# MCU_I3C0_VBP2APB_WRAP_CORE_VBP_MIPI_I3C_MST register map
Vendor: Texas Instruments
Registers are 32-bit, read-write, reset 0x0 unless marked. A register's access mark holds for its fields unless they carry their own. Offsets are as the file gives them; [hi:lo] are bit positions; {n}, {i} and the like mark numbered series; 'fields as' and 'values as' point back to an identical list.

## MCU_I3C0_VBP2APB_WRAP_CORE_VBP_MIPI_I3C_MST (part 2 of 2)
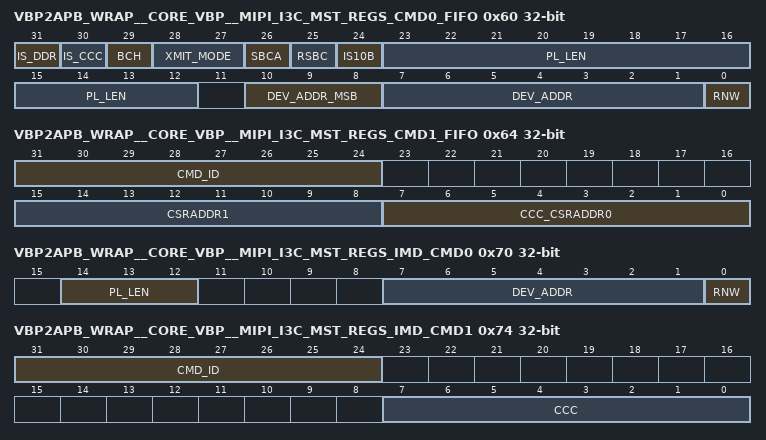
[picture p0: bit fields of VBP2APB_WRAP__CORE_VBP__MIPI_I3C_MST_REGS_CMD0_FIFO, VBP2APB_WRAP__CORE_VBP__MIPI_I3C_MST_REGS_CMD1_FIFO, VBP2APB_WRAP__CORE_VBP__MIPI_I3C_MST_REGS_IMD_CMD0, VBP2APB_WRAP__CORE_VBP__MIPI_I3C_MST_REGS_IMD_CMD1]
0x60 VBP2APB_WRAP__CORE_VBP__MIPI_I3C_MST_REGS_CMD0_FIFO wo — Command Word 0 - commands are executed sequentially in order of arrival from the host.
  [31] IS_DDR — IS_DDR - DDR command. Enables DDR mode of transfer. 0 - SDR mode 1 - DDR mode, note that ENTHDR-DDR CCC should precede any commands with DDR mode enabled.
  [30] IS_CCC — IsCCC. Denotes whether it is a CCC or generic command. 0 - generic command 1 - CCC command
  [29] BCH — BCH - Broadcast Header. Defines whether command will includes broadcast address header [0x7E] or not. Implicitly set for CCC commands. 0 - broadcast header disabled 1 - broadcast header enabled
  [28:27] XMIT_MODE — Defines transfer modes for I3C SDR private read/write commands [not CCC], the following options are available: 00 - burst [byte-by-byte] transfer with static register sub-address. Send static sub-address followed by data bytes only. 01 - single data byte transfers with auto incremented register sub-addressing. Each data byte is followed by repeated start condition and slave's sub-address is inremented explicitly. 10 - single data byte transfers without auto incremented register sub-addressing. Each data byte is followed by repeated start condition, register sub-address as in CMD descriptor for all transactions. 11 - burst [byte-by-byte] transfer without register sub-addressing, i.e. first data byte after the DA/SA is payload byte acquired from Tx DATA buffer.
  [26] SBCA — SBCA - Sixteen Bits CSR Addressing. Defines the CSR addressing mode for I3C private commands only. 0 - normal CSR addressing mode [8-bit] - ADDR0_7 - ADDR0_0 1 - extended CSR addressing mode [16-bit] - ADDR0_7 - ADDR0_0 and ADDR1_7 - ADDR1_0
  [25] RSBC — RSBC - Repeated Start Between Commands. When this bit is set then between commands he repeated start condition is issued instead stop condition. It is only applicable when there is more than one command is in the command queue and next command is for Slave device of same type. The stop condition will be generated regardless of RSCB bit value for the following scenarios: - current command is the last command in the command queue - next command has invalid DA/SA - immediate command comes through
  [24] IS10B — Is10B - Normal/Extended Address. Defines the addressing mode, applicable only for legacy I2C messaging. 0 - normal addressing mode [7-bit] - ID6-ID0 1 - extended addressing mode [10-bit] - ID10B2-ID10B0 and ID6-ID0
  [23:12] PL_LEN — PL_LEN - Payload Length, defines number of bytes to be sent for particular CCC or generic R/Q command. Supports up to 4095 bytes.
  [10:8] DEV_ADDR_MSB — DEV_ADDR_MSB - legacy I2C Extended Address. The 3 MSB bits of legacy I2C 10-bit address. Applicable only if Is_10B is set for I2C legacy transfers.
  [7:1] DEV_ADDR — DEV_ADDR - Static/Dynamic slave Address. Correspond to a given slave Dynamic Address and Static Address. For CCC is applicable only when it is direct CCC command. For broadcast CCC this field is ignored.
  [0] RNW — RnW - Read no Write. Defines the direction of transfer, for broadcast CCC this field is ignored. 0 - Write Transfer 1 - Read Transfer
0x64 VBP2APB_WRAP__CORE_VBP__MIPI_I3C_MST_REGS_CMD1_FIFO wo — Command Word 1 - commands are executed sequentially in order of arrival from host.
  [31:24] CMD_ID — CMD_ID - command identifier.
  [15:8] CSRADDR1 — CSR ADDR1 - second byte of the CSR address in 16-bit addressing mode. Applicable only when 16-bit addressing mode is used and for private commands [non CCC commands].
  [7:0] CCC_CSRADDR0 — CCC/CSR ADDR0 - CCC or CSR Address. Meaning of this field depends on bit 30 [IsCCC] of Command Word0. - When is_ccc is set to '0' then this field holds address of slave CSR. When 16-bit addressing is used, then it is the first byte of the CSR address. - When is ccc is set to '1' then this field holds code of CCC.
0x68 VBP2APB_WRAP__CORE_VBP__MIPI_I3C_MST_REGS_TX_FIFO wo — Tx DATA Buffer that stores payload to be send with associated Tx command descriptor (from regular Command Queue).
  [31:0] DATA — Tx DATA payload.
0x70 VBP2APB_WRAP__CORE_VBP__MIPI_I3C_MST_REGS_IMD_CMD0 wo — Immediate Command Word 0 - High priority command register. If host submits immediate command when controller is during execution of regular command, the core will run regular command to completion and then will execute the immediate command, disregarding state of Command Queue. Supposed to be used mainly for CCC commands with payload up to 4 bytes.
  [14:12] PL_LEN — PL_LEN - Payload Length, defines number of bytes to be send for particular CCC or generic R/W command. Supports up to 4 bytes.
  [7:1] DEV_ADDR — DEV_ADDR - Static/Dynamic slave Address. Correspond to a given slave Dynamic Address and Static Address. For CCC is applicable only when it is direct CCC command. For broadcast CCC this field is ignored.
  [0] RNW — RnW - Read not Write. Defines the direction of transfer, for broadcast CCC this field is ignored. 0 - Write Transfer 1 - Read Transfer
0x74 VBP2APB_WRAP__CORE_VBP__MIPI_I3C_MST_REGS_IMD_CMD1 wo — Immediate Command Word 1 - High priority command register. If host submits immediate command when controller is during execution of regular command, the core will run regular command to completion and then will execute the immediate command, disregarding state of Command Queue. Supposed to be used mainly for CCC commands with payload up to 4 bytes.
  [31:24] CMD_ID — CMD_ID - command identifier.
  [7:0] CCC — CCC Code - field holds code of CCC message.
0x78 VBP2APB_WRAP__CORE_VBP__MIPI_I3C_MST_REGS_IMD_DATA — Tx DATA Register that stores payload to be send with associated command descriptor (from Immediate Command Register).
  [31:0] DATA — Tx DATA payload [it's not a FIFO, supports up to 4 bytes only].
0x80 VBP2APB_WRAP__CORE_VBP__MIPI_I3C_MST_REGS_RX_FIFO ro — Rx DATA Buffer that stores payload received as a part of Rx command execution (from regular Command Queue).
  [31:0] DATA — Rx DATA payload.
0x84 VBP2APB_WRAP__CORE_VBP__MIPI_I3C_MST_REGS_IBI_DATA_FIFO ro — IBI Data Buffer that stores payload received as apart of IBI reuqest service.
  [31:0] DATA — IBI DATA payload.
0x88 VBP2APB_WRAP__CORE_VBP__MIPI_I3C_MST_REGS_SLV_DDR_TX_FIFO wo — Slave DDR Tx DATA Buffer that stores payload to be send upon reception of DDR read request from Current Master.
  [19:0] DDR_SLAVE_TX_DATA_FIFO — DDR Tx DATA payload [with meta-data, e.g. preamble/parity].
0x8C VBP2APB_WRAP__CORE_VBP__MIPI_I3C_MST_REGS_SLV_DDR_RX_FIFO ro — Slave DDR Rx DATA Buffer that stores payload received during reception of DDR write request from Current Master.
  [19:0] DDR_SLAVE_RX_DATA_FIFO — DDR Rx DATA payload [with meta-data, e.g. preamble/parity].
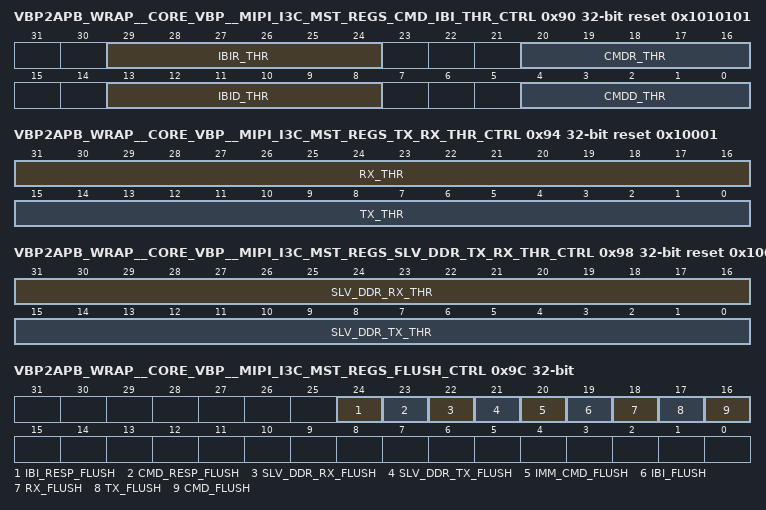
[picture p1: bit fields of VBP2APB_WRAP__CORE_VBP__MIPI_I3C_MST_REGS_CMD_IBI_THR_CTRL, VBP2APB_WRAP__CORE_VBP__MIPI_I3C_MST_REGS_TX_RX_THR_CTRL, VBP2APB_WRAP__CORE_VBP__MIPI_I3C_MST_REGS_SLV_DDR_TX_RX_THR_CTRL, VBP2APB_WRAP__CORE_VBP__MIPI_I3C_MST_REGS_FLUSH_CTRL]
0x90 VBP2APB_WRAP__CORE_VBP__MIPI_I3C_MST_REGS_CMD_IBI_THR_CTRL reset 0x1010101 — Control register for threshold generation - associated with Command and In-Band Interrupt memory blocks.
  [29:24] IBIR_THR — Threshold configuration value for IBI Response Queue.
  [20:16] CMDR_THR — Threshold configuration value for Command Response Queue.
  [13:8] IBID_THR — Threshold configuration value for IBI DATA Buffer.
  [4:0] CMDD_THR — Threshold configuration value for Command Queue.
0x94 VBP2APB_WRAP__CORE_VBP__MIPI_I3C_MST_REGS_TX_RX_THR_CTRL reset 0x10001 — Control register for threshold generation - associated with Tx and Rx DATA memory blocks.
  [31:16] RX_THR — Threshold configuration value for Rx Data memory block
  [15:0] TX_THR — Threshold configuration value for Tx Data memory block
0x98 VBP2APB_WRAP__CORE_VBP__MIPI_I3C_MST_REGS_SLV_DDR_TX_RX_THR_CTRL reset 0x10001 — Control register for threshold generation - associated with Slave Mode DDR Tx and Rx DATA memory blocks.
  [31:16] SLV_DDR_RX_THR — Threshold configuration value for Slave DDR Rx DATA buffer.
  [15:0] SLV_DDR_TX_THR — Threshold configuration value for Slave DDR Tx DATA buffer.
0x9C VBP2APB_WRAP__CORE_VBP__MIPI_I3C_MST_REGS_FLUSH_CTRL wo — Soft flush control for memory blocks.
  [24] IBI_RESP_FLUSH — When asserted while controller is disabled, the IBI Response Queue read/write pointers will be set to 0, effectively makes the buffer empty. Self-cleared control bit.
  [23] CMD_RESP_FLUSH — When asserted while controller is disabled, the Command Response Queue read/write pointers will be set to 0, effectively makes the buffer empty. Self-cleared control bit.
  [22] SLV_DDR_RX_FLUSH — When asserted while controller is disabled, the Slave DDR Rx DATA Buffer read/write pointers will be set to 0, effectively makes the buffer empty. Self-cleared control bit.
  [21] SLV_DDR_TX_FLUSH — When asserted while controller is disabled, the Slave DDR Tx DATA Buffer read/write pointers will be set to 0, effectively makes the buffer empty. Self-cleared control bit.
  [20] IMM_CMD_FLUSH — When asserted while controller is disabled, the Immediate Commadn/DATA registers will be cleared and their empty flag will be asserted. Self-cleared control bit.
  [19] IBI_FLUSH — When asserted while controller is disabled, the IBI DATA Buffer read/write pointers will be set to 0, effectively makes the buffer empty. Self-cleared control bit.
  [18] RX_FLUSH — When asserted while controller is disabled, the Rx DATA Buffer read/write pointers will be set to 0, effectively makes the buffer empty. Self-cleared control bit.. Self-cleared control bit.
  [17] TX_FLUSH — When asserted while controller is disabled, the Tx DATA Buffer read/write pointers will be set to 0, effectively makes the buffer empty. Self-cleared control bit.
  [16] CMD_FLUSH — When asserted while controller is disabled, the Command Buffer read/write pointers will be set to 0, effectively makes the buffer empty. Self-cleared control bit.
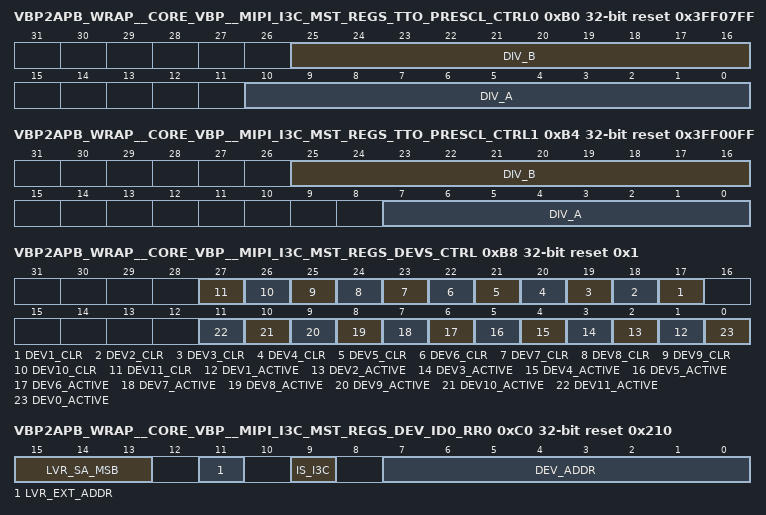
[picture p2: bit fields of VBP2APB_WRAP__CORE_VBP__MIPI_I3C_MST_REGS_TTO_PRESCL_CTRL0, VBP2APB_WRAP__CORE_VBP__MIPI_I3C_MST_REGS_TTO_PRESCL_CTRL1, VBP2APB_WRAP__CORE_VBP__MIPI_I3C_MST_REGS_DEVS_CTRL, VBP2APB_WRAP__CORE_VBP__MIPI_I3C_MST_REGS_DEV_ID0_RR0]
0xB0 VBP2APB_WRAP__CORE_VBP__MIPI_I3C_MST_REGS_TTO_PRESCL_CTRL0 reset 0x3FF07FF — Prescale settings for First SCL high timeout detection.
  [25:16] DIV_B — Divider B
  [10:0] DIV_A — Divider A
0xB4 VBP2APB_WRAP__CORE_VBP__MIPI_I3C_MST_REGS_TTO_PRESCL_CTRL1 reset 0x3FF00FF — Prescale settings for SCL high and low timeout detection.
  [25:16] DIV_B — Divider B
  [7:0] DIV_A — Divider A
0xB8 VBP2APB_WRAP__CORE_VBP__MIPI_I3C_MST_REGS_DEVS_CTRL access per field reset 0x1 — Device control register.
  [n+16] DEV{n}_CLR wo (n=1..11) — Clear contents of DevID{n} retaining registers. Self-cleared bit.
  [n] DEV{n}_ACTIVE rw (n=1..11) — DevID{n} is active - has either valid DA or SA.
  [0] DEV0_ACTIVE ro — DevID0 is active - has either valid DA or SA.
0xC0 VBP2APB_WRAP__CORE_VBP__MIPI_I3C_MST_REGS_DEV_ID0_RR0 access per field reset 0x210 — Device ID 0 Retaining Register 0 : Configuration Register
  [15:13] LVR_SA_MSB rw — MSB bits of Legacy I2C Device with 10-bit addressing.
  [11] LVR_EXT_ADDR rw — Device 0 Address mode used: 0 - 7-bit addressing - applicable for I3C and I2C devices. 1 - 10-bit addressing - applicable only for I2C devices with 10-bit extended address. NOTE: Invalid setting when Device0_RR0.is_i3c=1
  [9] IS_I3C ro — Device 0 I3C mode Operation 1 Yes 0 No
  [7:0] DEV_ADDR rw — Device 0 Slave Dynamic [Static/Legacy] Address bits 7:1 bit 0 - parity XOR check -> ~XOR[dev_addr[7:1]].
0xC4 VBP2APB_WRAP__CORE_VBP__MIPI_I3C_MST_REGS_DEV_ID0_RR1 reset 0x2040000 — Device ID 0 Retaining Register 1 : Provisional ID MSB 32-bits
  [31:0] PID_MSB — Device 0 48 to 16 Dev ID bits
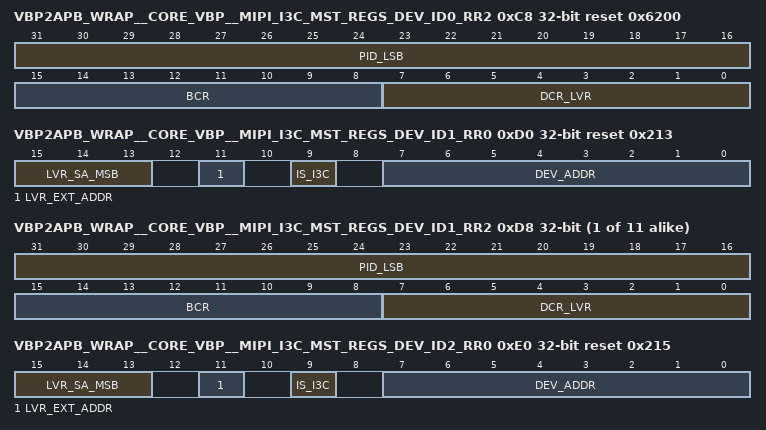
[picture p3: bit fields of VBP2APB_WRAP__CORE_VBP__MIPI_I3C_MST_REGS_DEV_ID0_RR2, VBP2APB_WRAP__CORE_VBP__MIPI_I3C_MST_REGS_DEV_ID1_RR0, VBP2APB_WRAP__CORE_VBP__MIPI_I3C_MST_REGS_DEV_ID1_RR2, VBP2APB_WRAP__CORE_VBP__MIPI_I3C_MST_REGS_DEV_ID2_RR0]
0xC8 VBP2APB_WRAP__CORE_VBP__MIPI_I3C_MST_REGS_DEV_ID0_RR2 reset 0x6200 — Device ID 0 Retaining Register 2 : Provisional ID LSB 16-bits, BCR, DCR or LVR (for legacy Mode)
  [31:16] PID_LSB — Device 0 15 to 0 Dev ID bits
  [15:8] BCR — Device 0 BCR register
  [7:0] DCR_LVR — Device 0 DCR [if I3C device] or LVR [if I2C device] register Decoding if used as DCR: Bits[7:0]: 255 available codes for describing the type of sensor, or Device; Decoding if used as LVR: Bits [7:4]: Device 0 LVR Code: 15 available codes for describing the Device capabilities and function on the sensors' system Bits [3:3]: Device 0 LVR Slave operation mode: 1'b0 FM mode 1'b1 FM+ mode Bits [2:0]: Device 0 LVR Index: 3'b000 Index 0 3'b001 Index 1 3'b010 Index 2 3'b011 Index 3 [Reserved] 3'b100 Index 4 [Reserved] 3'b101 Index 5 [Reserved] 3'b110 Index 6 [Reserved] 3'b111 Index 7 [Reserved]
0xD0 VBP2APB_WRAP__CORE_VBP__MIPI_I3C_MST_REGS_DEV_ID1_RR0 reset 0x213 — Device ID 1 Retaining Register 0 : Configuration Register
  [15:13] LVR_SA_MSB — MSB bits of Legacy I2C Device with 10-bit addressing.
  [11] LVR_EXT_ADDR — Device 1 Address mode used: 0 - 7-bit addressing - applicable for I3C and I2C devices. 1 - 10-bit addressing - applicable only for I2C devices with 10-bit extended address. NOTE: Invalid setting when Device1_RR0.is_i3c=1
  [9] IS_I3C — Device 1 I3C mode Operation 1 Yes 0 No
  [7:0] DEV_ADDR — Device 1 Slave Dynamic [Static/Legacy] Address bits 7:1 bit 0 - parity XOR check -> ~XOR[dev_addr[7:1]].
{0xC4+0x10*i} VBP2APB_WRAP__CORE_VBP__MIPI_I3C_MST_REGS_DEV_ID{i}_RR1 (i=1..11) — Device ID {i} Retaining Register 1 : Provisional ID MSB 32-bits
  [31:0] PID_MSB — Device {i} 48 to 16 Dev ID bits
{0xC8+0x10*i} VBP2APB_WRAP__CORE_VBP__MIPI_I3C_MST_REGS_DEV_ID{i}_RR2 (i=1..11) — Device ID {i} Retaining Register 2 : Provisional ID LSB 16-bits, BCR, DCR or LVR (for legacy Mode)
  [31:16] PID_LSB — Device {i} 15 to 0 Dev ID bits
  [15:8] BCR — Device {i} BCR register
  [7:0] DCR_LVR — Device {i} DCR [if I3C device] or LVR [if I2C device] register Decoding if used as DCR: Bits[7:0]: 255 available codes for describing the type of sensor, or Device; Decoding if used as LVR: Bits [7:4]: Device {i} LVR Code: 15 available codes for describing the Device capabilities and function on the sensors' system Bits [3:3]: Device {i} LVR Slave operation mode: 1'b0 FM mode 1'b1 FM+ mode Bits [2:0]: Device {i} LVR Index: 3'b000 Index 0 3'b001 Index 1 3'b010 Index 2 3'b011 Index 3 [Reserved] 3'b100 Index 4 [Reserved] 3'b101 Index 5 [Reserved] 3'b110 Index 6 [Reserved] 3'b111 Index 7 [Reserved]
0xE0 VBP2APB_WRAP__CORE_VBP__MIPI_I3C_MST_REGS_DEV_ID2_RR0 reset 0x215 — Device ID 2 Retaining Register 0 : Configuration Register
  [15:13] LVR_SA_MSB — MSB bits of Legacy I2C Device with 10-bit addressing.
  [11] LVR_EXT_ADDR — Device 2 Address mode used: 0 - 7-bit addressing - applicable for I3C and I2C devices. 1 - 10-bit addressing - applicable only for I2C devices with 10-bit extended address. NOTE: Invalid setting when Device2_RR0.is_i3c=1
  [9] IS_I3C — Device 2 I3C mode Operation 1 Yes 0 No
  [7:0] DEV_ADDR — Device 2 Slave Dynamic [Static/Legacy] Address bits 7:1 bit 0 - parity XOR check -> ~XOR[dev_addr[7:1]].
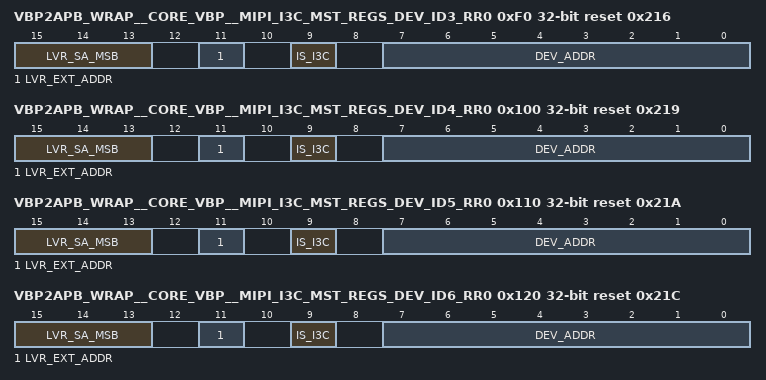
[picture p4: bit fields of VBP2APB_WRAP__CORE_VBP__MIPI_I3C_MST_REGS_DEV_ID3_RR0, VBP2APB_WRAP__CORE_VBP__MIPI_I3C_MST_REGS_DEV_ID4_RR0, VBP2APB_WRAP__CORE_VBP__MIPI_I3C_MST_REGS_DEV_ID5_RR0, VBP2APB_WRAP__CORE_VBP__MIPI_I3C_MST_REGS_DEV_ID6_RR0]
0xF0 VBP2APB_WRAP__CORE_VBP__MIPI_I3C_MST_REGS_DEV_ID3_RR0 reset 0x216 — Device ID 3 Retaining Register 0 : Configuration Register
  [15:13] LVR_SA_MSB — MSB bits of Legacy I2C Device with 10-bit addressing.
  [11] LVR_EXT_ADDR — Device 3 Address mode used: 0 - 7-bit addressing - applicable for I3C and I2C devices. 1 - 10-bit addressing - applicable only for I2C devices with 10-bit extended address. NOTE: Invalid setting when Device3_RR0.is_i3c=1
  [9] IS_I3C — Device 3 I3C mode Operation 1 Yes 0 No
  [7:0] DEV_ADDR — Device 3 Slave Dynamic [Static/Legacy] Address bits 7:1 bit 0 - parity XOR check -> ~XOR[dev_addr[7:1]].
0x100 VBP2APB_WRAP__CORE_VBP__MIPI_I3C_MST_REGS_DEV_ID4_RR0 reset 0x219 — Device ID 4 Retaining Register 0 : Configuration Register
  [15:13] LVR_SA_MSB — MSB bits of Legacy I2C Device with 10-bit addressing.
  [11] LVR_EXT_ADDR — Device 4 Address mode used: 0 - 7-bit addressing - applicable for I3C and I2C devices. 1 - 10-bit addressing - applicable only for I2C devices with 10-bit extended address. NOTE: Invalid setting when Device4_RR0.is_i3c=1
  [9] IS_I3C — Device 4 I3C mode Operation 1 Yes 0 No
  [7:0] DEV_ADDR — Device 4 Slave Dynamic [Static/Legacy] Address bits 7:1 bit 0 - parity XOR check -> ~XOR[dev_addr[7:1]].
0x110 VBP2APB_WRAP__CORE_VBP__MIPI_I3C_MST_REGS_DEV_ID5_RR0 reset 0x21A — Device ID 5 Retaining Register 0 : Configuration Register
  [15:13] LVR_SA_MSB — MSB bits of Legacy I2C Device with 10-bit addressing.
  [11] LVR_EXT_ADDR — Device 5 Address mode used: 0 - 7-bit addressing - applicable for I3C and I2C devices. 1 - 10-bit addressing - applicable only for I2C devices with 10-bit extended address. NOTE: Invalid setting when Device5_RR0.is_i3c=1
  [9] IS_I3C — Device 5 I3C mode Operation 1 Yes 0 No
  [7:0] DEV_ADDR — Device 5 Slave Dynamic [Static/Legacy] Address bits 7:1 bit 0 - parity XOR check -> ~XOR[dev_addr[7:1]].
0x120 VBP2APB_WRAP__CORE_VBP__MIPI_I3C_MST_REGS_DEV_ID6_RR0 reset 0x21C — Device ID 6 Retaining Register 0 : Configuration Register
  [15:13] LVR_SA_MSB — MSB bits of Legacy I2C Device with 10-bit addressing.
  [11] LVR_EXT_ADDR — Device 6 Address mode used: 0 - 7-bit addressing - applicable for I3C and I2C devices. 1 - 10-bit addressing - applicable only for I2C devices with 10-bit extended address. NOTE: Invalid setting when Device6_RR0.is_i3c=1
  [9] IS_I3C — Device 6 I3C mode Operation 1 Yes 0 No
  [7:0] DEV_ADDR — Device 6 Slave Dynamic [Static/Legacy] Address bits 7:1 bit 0 - parity XOR check -> ~XOR[dev_addr[7:1]].
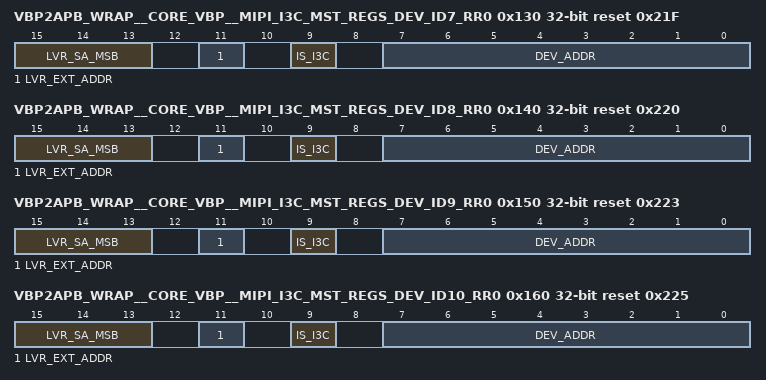
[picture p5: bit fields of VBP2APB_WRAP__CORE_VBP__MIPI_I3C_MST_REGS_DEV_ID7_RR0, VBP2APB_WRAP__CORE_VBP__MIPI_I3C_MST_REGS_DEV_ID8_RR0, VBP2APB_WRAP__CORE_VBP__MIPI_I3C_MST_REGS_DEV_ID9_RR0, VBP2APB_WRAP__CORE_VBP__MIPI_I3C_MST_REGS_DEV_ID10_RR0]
0x130 VBP2APB_WRAP__CORE_VBP__MIPI_I3C_MST_REGS_DEV_ID7_RR0 reset 0x21F — Device ID 7 Retaining Register 0 : Configuration Register
  [15:13] LVR_SA_MSB — MSB bits of Legacy I2C Device with 10-bit addressing.
  [11] LVR_EXT_ADDR — Device 7 Address mode used: 0 - 7-bit addressing - applicable for I3C and I2C devices. 1 - 10-bit addressing - applicable only for I2C devices with 10-bit extended address. NOTE: Invalid setting when Device7_RR0.is_i3c=1
  [9] IS_I3C — Device 7 I3C mode Operation 1 Yes 0 No
  [7:0] DEV_ADDR — Device 7 Slave Dynamic [Static/Legacy] Address bits 7:1 bit 0 - parity XOR check -> ~XOR[dev_addr[7:1]].
0x140 VBP2APB_WRAP__CORE_VBP__MIPI_I3C_MST_REGS_DEV_ID8_RR0 reset 0x220 — Device ID 8 Retaining Register 0 : Configuration Register
  [15:13] LVR_SA_MSB — MSB bits of Legacy I2C Device with 10-bit addressing.
  [11] LVR_EXT_ADDR — Device 8 Address mode used: 0 - 7-bit addressing - applicable for I3C and I2C devices. 1 - 10-bit addressing - applicable only for I2C devices with 10-bit extended address. NOTE: Invalid setting when Device8_RR0.is_i3c=1
  [9] IS_I3C — Device 8 I3C mode Operation 1 Yes 0 No
  [7:0] DEV_ADDR — Device 8 Slave Dynamic [Static/Legacy] Address bits 7:1 bit 0 - parity XOR check -> ~XOR[dev_addr[7:1]].
0x150 VBP2APB_WRAP__CORE_VBP__MIPI_I3C_MST_REGS_DEV_ID9_RR0 reset 0x223 — Device ID 9 Retaining Register 0 : Configuration Register
  [15:13] LVR_SA_MSB — MSB bits of Legacy I2C Device with 10-bit addressing.
  [11] LVR_EXT_ADDR — Device 9 Address mode used: 0 - 7-bit addressing - applicable for I3C and I2C devices. 1 - 10-bit addressing - applicable only for I2C devices with 10-bit extended address. NOTE: Invalid setting when Device9_RR0.is_i3c=1
  [9] IS_I3C — Device 9 I3C mode Operation 1 Yes 0 No
  [7:0] DEV_ADDR — Device 9 Slave Dynamic [Static/Legacy] Address bits 7:1 bit 0 - parity XOR check -> ~XOR[dev_addr[7:1]].
0x160 VBP2APB_WRAP__CORE_VBP__MIPI_I3C_MST_REGS_DEV_ID10_RR0 reset 0x225 — Device ID 10 Retaining Register 0 : Configuration Register
  [15:13] LVR_SA_MSB — MSB bits of Legacy I2C Device with 10-bit addressing.
  [11] LVR_EXT_ADDR — Device 10 Address mode used: 0 - 7-bit addressing - applicable for I3C and I2C devices. 1 - 10-bit addressing - applicable only for I2C devices with 10-bit extended address. NOTE: Invalid setting when Device10_RR0.is_i3c=1
  [9] IS_I3C — Device 10 I3C mode Operation 1 Yes 0 No
  [7:0] DEV_ADDR — Device 10 Slave Dynamic [Static/Legacy] Address bits 7:1 bit 0 - parity XOR check -> ~XOR[dev_addr[7:1]].
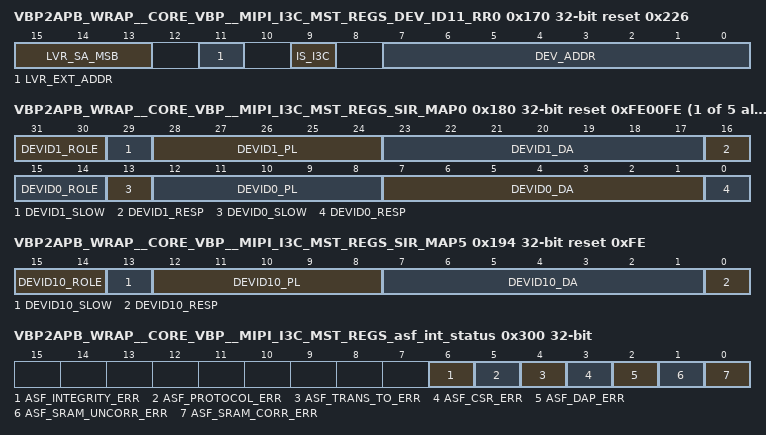
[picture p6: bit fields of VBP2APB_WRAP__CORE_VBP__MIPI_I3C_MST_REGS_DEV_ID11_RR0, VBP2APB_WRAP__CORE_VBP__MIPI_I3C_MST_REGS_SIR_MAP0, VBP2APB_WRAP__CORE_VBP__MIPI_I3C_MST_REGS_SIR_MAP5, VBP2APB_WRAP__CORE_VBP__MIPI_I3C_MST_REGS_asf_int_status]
0x170 VBP2APB_WRAP__CORE_VBP__MIPI_I3C_MST_REGS_DEV_ID11_RR0 reset 0x226 — Device ID 11 Retaining Register 0 : Configuration Register
  [15:13] LVR_SA_MSB — MSB bits of Legacy I2C Device with 10-bit addressing.
  [11] LVR_EXT_ADDR — Device 11 Address mode used: 0 - 7-bit addressing - applicable for I3C and I2C devices. 1 - 10-bit addressing - applicable only for I2C devices with 10-bit extended address. NOTE: Invalid setting when Device11_RR0.is_i3c=1
  [9] IS_I3C — Device 11 I3C mode Operation 1 Yes 0 No
  [7:0] DEV_ADDR — Device 11 Slave Dynamic [Static/Legacy] Address bits 7:1 bit 0 - parity XOR check -> ~XOR[dev_addr[7:1]].
{0x180+4i} VBP2APB_WRAP__CORE_VBP__MIPI_I3C_MST_REGS_SIR_MAP{i} reset 0xFE00FE (i=0..4) — Slave-initiated request Device ID Detection register{i}
  [31:30] DEVID{2i+1}_ROLE — Slave-initiated request Device ID{2i} BCR role 2'b00 - Slave 2'b01 - Master/Secondary Master 2'b10 - Reserved 2'b11 - Reserved
  [29] DEVID{2i+1}_SLOW — Slave-initiated request Device ID{2i} Max Data Speed Limitation 0 - No limitation 1 - Limitation
  [28:24] DEVID{2i+1}_PL — Slave-initiated request Device ID{2i} payload length
  [23:17] DEVID{2i+1}_DA — Slave-initiated request Device ID{2i} DA
  [16] DEVID{2i+1}_RESP — Slave-initiated request Device ID{2i} Ack/Nack response 0 - NACK each request from this device. 1 - ACK each request from this device.
  [15:14] DEVID{2i}_ROLE — Slave-initiated request Device ID{2i} BCR role 2'b00 - Slave 2'b01 - Master/Secondary Master 2'b10 - Reserved 2'b11 - Reserved
  [13] DEVID{2i}_SLOW — Slave-initiated request Device ID{2i} Max Data Speed Limitation 0 - No limitation 1 - Limitation
  [12:8] DEVID{2i}_PL — Slave-initiated request Device ID{2i} payload length
  [7:1] DEVID{2i}_DA — Slave-initiated request Device ID{2i} DA
  [0] DEVID{2i}_RESP — Slave-initiated request Device ID{2i} Ack/Nack response 0 - NACK each request from this device. 1 - ACK each request from this device.
0x194 VBP2APB_WRAP__CORE_VBP__MIPI_I3C_MST_REGS_SIR_MAP5 reset 0xFE — Slave-initiated request Device ID Detection register5
  [15:14] DEVID10_ROLE — Slave-initiated request Device ID10 BCR role 2'b00 - Slave 2'b01 - Master/Secondary Master 2'b10 - Reserved 2'b11 - Reserved
  [13] DEVID10_SLOW — Slave-initiated request Device ID10 Max Data Speed Limitation 0 - No limitation 1 - Limitation
  [12:8] DEVID10_PL — Slave-initiated request Device ID10 payload length
  [7:1] DEVID10_DA — Slave-initiated request Device ID10 DA
  [0] DEVID10_RESP — Slave-initiated request Device ID10 Ack/Nack response 0 - NACK each request from this device. 1 - ACK each request from this device.
0x1A0 VBP2APB_WRAP__CORE_VBP__MIPI_I3C_MST_REGS_GPIR_WORD0 ro — User Defined GPI Word 0: four 8-bits GPI Registers
  [7:0] GPI0 — User Defined GPI Register 0
0x220 VBP2APB_WRAP__CORE_VBP__MIPI_I3C_MST_REGS_GPOR_WORD0 ro — User Defined GPO Word 0: four 8-bits GPO Registers
  [7:0] GPO0 — User Defined GPO Register 0
0x300 VBP2APB_WRAP__CORE_VBP__MIPI_I3C_MST_REGS_asf_int_status access not given — ASF Interrupt Status Register. This register indicates the source of ASF interrupts. The corresponding bit in the mask register must be clear for a bit to be set. If any bit is set in this register the asf_fatal or asf_nonfatal signal will be asserted. Writing to either raw or masked status registers, clear both registers. For test purposes, trigger signal interrupt event by writing to the ASF interrupt status test register.
  [6] ASF_INTEGRITY_ERR — Integrity error interrupt (access R/W1TC)
  [5] ASF_PROTOCOL_ERR — Protocol error interrupt (access R/W1TC)
  [4] ASF_TRANS_TO_ERR — Transaction timeouts error interrupt (access R/W1TC)
  [3] ASF_CSR_ERR — Configuration and status registers error interrupt (access R/W1TC)
  [2] ASF_DAP_ERR — Data and address paths parity error interrupt (access R/W1TC)
  [1] ASF_SRAM_UNCORR_ERR — SRAM uncorrectable error interrupt (access R/W1TC)
  [0] ASF_SRAM_CORR_ERR — SRAM correctable error interrupt (access R/W1TC)
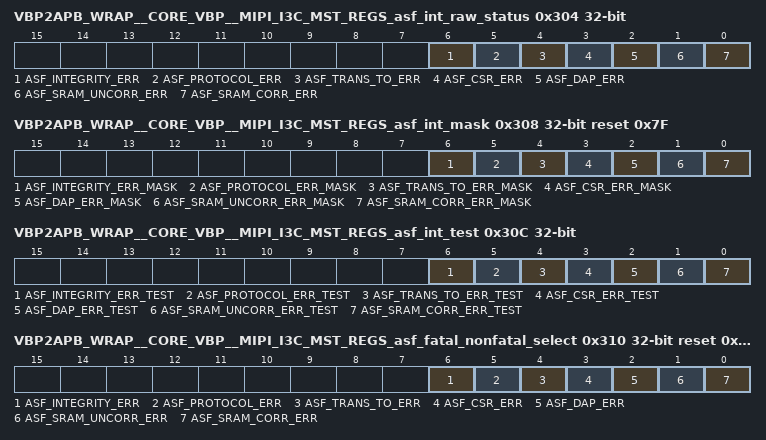
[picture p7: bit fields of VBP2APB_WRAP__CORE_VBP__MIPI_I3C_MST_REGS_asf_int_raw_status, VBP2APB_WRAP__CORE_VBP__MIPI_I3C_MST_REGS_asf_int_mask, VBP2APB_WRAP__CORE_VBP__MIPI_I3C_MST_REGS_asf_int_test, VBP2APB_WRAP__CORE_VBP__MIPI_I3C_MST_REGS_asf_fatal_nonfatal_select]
0x304 VBP2APB_WRAP__CORE_VBP__MIPI_I3C_MST_REGS_asf_int_raw_status access not given — ASF Interrupt Raw Status Register. A bit set in this raw register indicates a source of ASF fault in the corresponding feature. Writing to either raw or masked status registers, clear both registers. For test purposes, trigger signal interrupt event by writing to the ASF interrupt status test register.
  fields as VBP2APB_WRAP__CORE_VBP__MIPI_I3C_MST_REGS_asf_int_status
0x308 VBP2APB_WRAP__CORE_VBP__MIPI_I3C_MST_REGS_asf_int_mask access not given reset 0x7F — The ASF interrupt mask register indicating which interrupt bits in the ASF interrupt status register are masked. All bits are set at reset. Clear the individual bit to enable the corresponding interrupt.
  [6] ASF_INTEGRITY_ERR_MASK rw — Mask bit for integrity error interrupt
  [5] ASF_PROTOCOL_ERR_MASK rw — Mask bit for protocol error interrupt.
  [4] ASF_TRANS_TO_ERR_MASK rw — Mask bit for transaction timeouts error interrupt.
  [3] ASF_CSR_ERR_MASK rw — Mask bit for configuration and status registers error interrupt.
  [2] ASF_DAP_ERR_MASK rw — Mask bit for data and address paths parity error interrupt.
  [1] ASF_SRAM_UNCORR_ERR_MASK rw — Mask bit for SRAM uncorrectable error interrupt.
  [0] ASF_SRAM_CORR_ERR_MASK rw — Mask bit for SRAM correctable error interrupt.
0x30C VBP2APB_WRAP__CORE_VBP__MIPI_I3C_MST_REGS_asf_int_test access not given — The ASF interrupt test register emulate hardware even. Write one to individual bit to trigger single event in (masked and raw) status registers according to mask and will generate interrupt accordingly.
  [6] ASF_INTEGRITY_ERR_TEST wo — Test bit for integrity error interrupt
  [5] ASF_PROTOCOL_ERR_TEST wo — Test bit for protocol error interrupt.
  [4] ASF_TRANS_TO_ERR_TEST wo — Test bit for transaction timeouts error interrupt.
  [3] ASF_CSR_ERR_TEST wo — Test bit for configuration and status registers error interrupt.
  [2] ASF_DAP_ERR_TEST wo — Test bit for data and address paths parity error interrupt.
  [1] ASF_SRAM_UNCORR_ERR_TEST wo — Test bit for SRAM uncorrectable error interrupt.
  [0] ASF_SRAM_CORR_ERR_TEST wo — Test bit for SRAM correctable error interrupt.
0x310 VBP2APB_WRAP__CORE_VBP__MIPI_I3C_MST_REGS_asf_fatal_nonfatal_select access not given reset 0x7F — The fatal or non-fatal interrupt register selects whether a fatal (asf_int_fatal) or non-fatal (asf_int_nonfatal) interrupt is triggered. If the bit of the event will be set to one then fatal interrupt (asf_int_fatal) will be triggered. Otherwise the non-fatal interrupt (asf_int_nonfatal) will be triggered.
  [6] ASF_INTEGRITY_ERR rw — Enable integrity error interrupt as fatal
  [5] ASF_PROTOCOL_ERR rw — Enable protocol error interrupt as fatal.
  [4] ASF_TRANS_TO_ERR rw — Enable transaction timeouts error interrupt as fatal.
  [3] ASF_CSR_ERR rw — Enable configuration and status registers error interrupt as fatal.
  [2] ASF_DAP_ERR rw — Enable data and address paths parity error interrupt as fatal.
  [1] ASF_SRAM_UNCORR_ERR rw — Enable SRAM uncorrectable error interrupt as fatal.
  [0] ASF_SRAM_CORR_ERR rw — Enable SRAM correctable error interrupt as fatal.
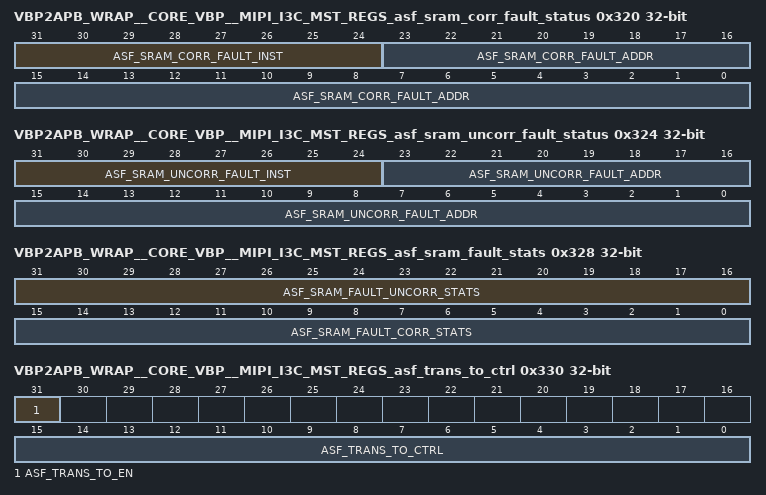
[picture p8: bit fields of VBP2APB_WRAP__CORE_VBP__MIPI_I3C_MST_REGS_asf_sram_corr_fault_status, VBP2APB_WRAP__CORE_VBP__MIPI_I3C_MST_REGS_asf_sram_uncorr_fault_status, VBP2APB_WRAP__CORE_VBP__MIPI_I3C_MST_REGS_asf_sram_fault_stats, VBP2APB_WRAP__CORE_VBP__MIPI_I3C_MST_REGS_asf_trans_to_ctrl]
0x320 VBP2APB_WRAP__CORE_VBP__MIPI_I3C_MST_REGS_asf_sram_corr_fault_status ro — Status register for SRAM correctable fault. These fields are updated whenever asf_sram_corr_fault input is active.
  [31:24] ASF_SRAM_CORR_FAULT_INST — Last SRAM instance that generated fault.
  [23:0] ASF_SRAM_CORR_FAULT_ADDR — Last SRAM address that generated fault.
0x324 VBP2APB_WRAP__CORE_VBP__MIPI_I3C_MST_REGS_asf_sram_uncorr_fault_status ro — Status register for SRAM uncorrectable fault. These fields are updated whenever asf_sram_uncorr_fault input is active.
  [31:24] ASF_SRAM_UNCORR_FAULT_INST — Last SRAM instance that generated fault.
  [23:0] ASF_SRAM_UNCORR_FAULT_ADDR — Last SRAM address that generated fault.
0x328 VBP2APB_WRAP__CORE_VBP__MIPI_I3C_MST_REGS_asf_sram_fault_stats access not given — Statistics register for SRAM faults. Note that this register clears when software writes to any field.
  [31:16] ASF_SRAM_FAULT_UNCORR_STATS — Count of number of uncorrectable errors if implemented. Count value will saturate at 0xffff. (access R/W1TC)
  [15:0] ASF_SRAM_FAULT_CORR_STATS — Count of number of correctable errors if implemented. Count value will saturate at 0xffff. (access R/W1TC)
0x330 VBP2APB_WRAP__CORE_VBP__MIPI_I3C_MST_REGS_asf_trans_to_ctrl access not given — Control register to configure the ASF transaction timeout monitors.
  [31] ASF_TRANS_TO_EN rw — Enable transaction timeout monitoring.
  [15:0] ASF_TRANS_TO_CTRL rw — Timer value to use for transaction timeout monitor.
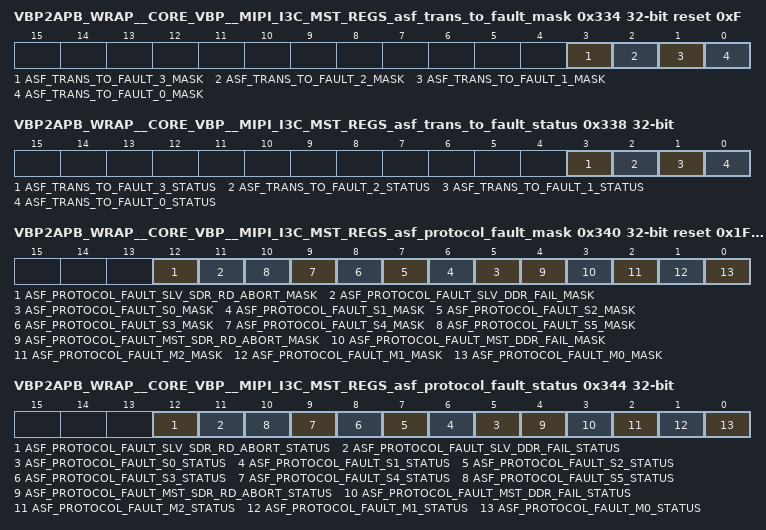
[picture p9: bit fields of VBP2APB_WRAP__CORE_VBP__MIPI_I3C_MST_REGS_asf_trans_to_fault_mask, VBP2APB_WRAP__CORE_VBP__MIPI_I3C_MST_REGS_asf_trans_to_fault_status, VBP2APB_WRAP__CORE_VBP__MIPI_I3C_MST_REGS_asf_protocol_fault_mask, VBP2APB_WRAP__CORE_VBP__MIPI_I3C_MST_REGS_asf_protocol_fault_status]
0x334 VBP2APB_WRAP__CORE_VBP__MIPI_I3C_MST_REGS_asf_trans_to_fault_mask access not given reset 0xF — Control register to mask out ASF transaction timeout faults from triggering interrupts. On reset, all bits are set to mask out all sources. Clear the corresponding bit to enable the interrupt source. The width of this field is parameterizable and the bit definitions are implementation specific.
  [3] ASF_TRANS_TO_FAULT_3_MASK rw — Mask bit for apb transaction timeout fault.
  [2] ASF_TRANS_TO_FAULT_2_MASK rw — Mask bit for I3C transaction SCL low timeout fault.
  [1] ASF_TRANS_TO_FAULT_1_MASK rw — Mask bit for I3C transaction SCL high timeout fault.
  [0] ASF_TRANS_TO_FAULT_0_MASK rw — Mask bit for I3C transaction first SCL high timeout fault.
0x338 VBP2APB_WRAP__CORE_VBP__MIPI_I3C_MST_REGS_asf_trans_to_fault_status access not given — Status register for transaction timeouts fault. If a fault occurs the relevant status bit will be set to 1. Each bit can be cleared by software writing 1 to each bit.
  [3] ASF_TRANS_TO_FAULT_3_STATUS — Status bits for apb transaction timeout fault. (access R/W1TC)
  [2] ASF_TRANS_TO_FAULT_2_STATUS — Status bits for I3C transaction SCL low timeout fault. (access R/W1TC)
  [1] ASF_TRANS_TO_FAULT_1_STATUS — Status bits for I3C transaction SCL high timeout fault. (access R/W1TC)
  [0] ASF_TRANS_TO_FAULT_0_STATUS — Status bits for I3C transaction first SCL high timeout fault. (access R/W1TC)
0x340 VBP2APB_WRAP__CORE_VBP__MIPI_I3C_MST_REGS_asf_protocol_fault_mask access not given reset 0x1FFF — Control register to mask out ASF Protocol faults from triggering interrupts. On reset, all bits are set to mask out all sources. Clear the corresponding bit to enable the interrupt source. The width of this field is parameterisable and the bit definitions are implementation specific.
  [12] ASF_PROTOCOL_FAULT_SLV_SDR_RD_ABORT_MASK rw — Mask bit for slv_sdr_rd_abort protocol fault source.
  [11] ASF_PROTOCOL_FAULT_SLV_DDR_FAIL_MASK rw — Mask bit for slv_ddr_fail protocol fault source.
  [n+5] ASF_PROTOCOL_FAULT_S{n}_MASK rw (n=0..5) — Mask bit for s{n} protocol fault source.
  [4] ASF_PROTOCOL_FAULT_MST_SDR_RD_ABORT_MASK rw — Mask bit for mst_sdr_rd_abort protocol fault source.
  [3] ASF_PROTOCOL_FAULT_MST_DDR_FAIL_MASK rw — Mask bit for mst_ddr_fail protocol fault source.
  [2] ASF_PROTOCOL_FAULT_M2_MASK rw — Mask bit for m2 protocol fault source.
  [1] ASF_PROTOCOL_FAULT_M1_MASK rw — Mask bit for m1 protocol fault source.
  [0] ASF_PROTOCOL_FAULT_M0_MASK rw — Mask bit for m0 protocol fault source.
0x344 VBP2APB_WRAP__CORE_VBP__MIPI_I3C_MST_REGS_asf_protocol_fault_status access not given — Status register for protocol faults. If a fault occurs the relevant status bit will be set to 1. Each bit can be cleared by software writing 1 to each bit
  [12] ASF_PROTOCOL_FAULT_SLV_SDR_RD_ABORT_STATUS — Status bit for slv_sdr_rd_abort protocol fault. (access R/W1TC)
  [11] ASF_PROTOCOL_FAULT_SLV_DDR_FAIL_STATUS — Status bit for slv_ddr_fail protocol fault. (access R/W1TC)
  [n+5] ASF_PROTOCOL_FAULT_S{n}_STATUS (n=0..5) — Status bit for s{n} protocol fault. (access R/W1TC)
  [4] ASF_PROTOCOL_FAULT_MST_SDR_RD_ABORT_STATUS — Status bit for mst_sdr_rd_abort protocol fault. (access R/W1TC)
  [3] ASF_PROTOCOL_FAULT_MST_DDR_FAIL_STATUS — Status bit for mst_ddr_fail protocol fault. (access R/W1TC)
  [2] ASF_PROTOCOL_FAULT_M2_STATUS — Status bit for m2 protocol fault. (access R/W1TC)
  [1] ASF_PROTOCOL_FAULT_M1_STATUS — Status bit for m1 protocol fault. (access R/W1TC)
  [0] ASF_PROTOCOL_FAULT_M0_STATUS — Status bit for m0 protocol fault. (access R/W1TC)
